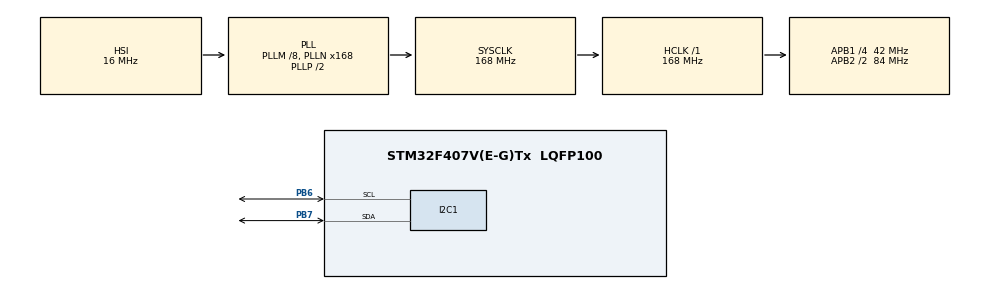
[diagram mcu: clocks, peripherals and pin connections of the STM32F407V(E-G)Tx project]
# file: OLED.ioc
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ADC1.Channel-0\#ChannelRegularConversion=ADC_CHANNEL_TEMPSENSOR
ADC1.NbrOfConversionFlag=1
ADC1.master=1
Dma.I2C1_TX.0.Direction=DMA_MEMORY_TO_PERIPH
Dma.I2C1_TX.0.FIFOMode=DMA_FIFOMODE_DISABLE
Dma.I2C1_TX.0.Instance=DMA1_Stream6
Dma.I2C1_TX.0.MemDataAlignment=DMA_MDATAALIGN_BYTE
Dma.I2C1_TX.0.MemInc=DMA_MINC_ENABLE
Dma.I2C1_TX.0.Mode=DMA_NORMAL
Dma.I2C1_TX.0.PeriphDataAlignment=DMA_PDATAALIGN_BYTE
Dma.I2C1_TX.0.PeriphInc=DMA_PINC_DISABLE
Dma.I2C1_TX.0.Priority=DMA_PRIORITY_LOW
Dma.Request0=I2C1_TX
I2C1.I2C_Mode=I2C_Fast
Mcu.Family=STM32F4
Mcu.Name=STM32F407V(E-G)Tx
Mcu.Package=LQFP100
NVIC.DMA1_Stream6_IRQn=true\:0\:0\:false\:false\:true\:false\:true\:true
NVIC.I2C1_ER_IRQn=true\:0\:0\:false\:false\:true\:true\:true\:true
NVIC.I2C1_EV_IRQn=true\:0\:0\:false\:false\:true\:true\:true\:true
NVIC.PriorityGroup=NVIC_PRIORITYGROUP_4
PA13.Mode=Serial_Wire
PA13.Signal=SYS_JTMS-SWDIO
PA14.Mode=Serial_Wire
PA14.Signal=SYS_JTCK-SWCLK
PB6.Mode=I2C
PB6.Signal=I2C1_SCL
PB7.Mode=I2C
PB7.Signal=I2C1_SDA
PH0-OSC_IN.Mode=HSE-External-Oscillator
PH0-OSC_IN.Signal=RCC_OSC_IN
PH1-OSC_OUT.Mode=HSE-External-Oscillator
PH1-OSC_OUT.Signal=RCC_OSC_OUT
ProjectManager.HeapSize=0x200
ProjectManager.StackSize=0x400
ProjectManager.TargetToolchain=STM32CubeIDE
RCC.48MHZClocksFreq_Value=84000000
RCC.AHBFreq_Value=168000000
RCC.APB1CLKDivider=RCC_HCLK_DIV4
RCC.APB1Freq_Value=42000000
RCC.APB1TimFreq_Value=84000000
RCC.APB2CLKDivider=RCC_HCLK_DIV2
RCC.APB2Freq_Value=84000000
RCC.APB2TimFreq_Value=168000000
RCC.CortexFreq_Value=168000000
RCC.HCLKFreq_Value=168000000
RCC.HSE_VALUE=25000000
RCC.HSI_VALUE=16000000
RCC.PLLM=8
RCC.PLLN=168
RCC.SYSCLKFreq_VALUE=168000000
RCC.SYSCLKSource=RCC_SYSCLKSOURCE_PLLCLK
RCC.VCOOutputFreq_Value=336000000
RTC.Date=28
RTC.Hours=20
RTC.Minutes=47
RTC.Month=RTC_MONTH_DECEMBER
RTC.WeekDay=RTC_WEEKDAY_THURSDAY
RTC.Year=24
VP_ADC1_TempSens_Input.Mode=IN-TempSens
VP_RTC_VS_RTC_Activate.Mode=RTC_Enabled
VP_RTC_VS_RTC_Calendar.Mode=RTC_Calendar
board=custom

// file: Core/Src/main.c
/* USER CODE BEGIN Header */
/**
  ******************************************************************************
  * @file           : main.c
  * @brief          : Main program body
  ******************************************************************************
  * @attention
  *
  * Copyright (c) 2023 STMicroelectronics.
  * All rights reserved.
  *
  * This software is licensed under terms that can be found in the LICENSE file
  * in the root directory of this software component.
  * If no LICENSE file comes with this software, it is provided AS-IS.
  *
  ******************************************************************************
  */
/* USER CODE END Header */
#include "main.h"
#include "adc.h"
#include "dma.h"
#include "i2c.h"
#include "rtc.h"
#include "gpio.h"

/* USER CODE BEGIN Includes */
#include <ic1306.h>
/* USER CODE END Includes */

/* USER CODE BEGIN PV */

RTC_TimeTypeDef sTime = {0};
RTC_DateTypeDef DateToUpdate = {0};

/* USER CODE END PV */

void SystemClock_Config(void);

int main(void)
{

  /* MCU Configuration--------------------------------------------------------*/

  /* Reset of all peripherals, Initializes the Flash interface and the Systick. */
  HAL_Init();

  /* Configure the system clock */
  SystemClock_Config();

  /* Initialize all configured peripherals */
  MX_GPIO_Init();
  MX_DMA_Init();
  MX_I2C1_Init();
  MX_RTC_Init();
  MX_ADC1_Init();
  /* USER CODE BEGIN 2 */
  display_init (0x30,0x22);

  display_clear(0,7);

 // display_MediumPrint(3,1,"Hello,");
 // display_MediumPrint(3,4,"PRO!");

  /* USER CODE END 2 */

  /* Infinite loop */
  /* USER CODE BEGIN WHILE */

 char trans_str[64] = {0,};
 int32_t ts = 0;
 while (1)
  {
  HAL_RTC_GetTime(&hrtc, &sTime, RTC_FORMAT_BIN); // RTC_FORMAT_BIN , RTC_FORMAT_BCD
  snprintf(trans_str, 63, " %02d:%02d:%02d\n", sTime.Hours, sTime.Minutes, sTime.Seconds);
  display_MediumPrint(0,1,trans_str);

  HAL_RTC_GetDate(&hrtc, &DateToUpdate, RTC_FORMAT_BIN);
  HAL_ADC_Start(&hadc1);
  HAL_ADC_PollForConversion(&hadc1, 100);
  ts = HAL_ADC_GetValue(&hadc1);
  snprintf(trans_str, 63, "Ts %d\n", ts);
  display_MediumPrint(2,3,trans_str);
  //temp = (Vtemp -tV_25)/tSlope + 25; (Vtemp-0,76V)/2,5mV
  snprintf(trans_str, 63, "Temp %d\n",(ts*33-31130)/102+25);
  display_MediumPrint(2,6,trans_str);

  HAL_RTC_GetDate(&hrtc, &DateToUpdate, RTC_FORMAT_BIN);
  snprintf(trans_str, 63, "%d-%02d-20%d\n", DateToUpdate.Date, DateToUpdate.Month, DateToUpdate.Year);
  //display_MediumPrint(0,4,trans_str);
  HAL_Delay(1000);
    /* USER CODE END WHILE */

  }
}

void SystemClock_Config(void)
{
  RCC_OscInitTypeDef RCC_OscInitStruct = {0};
  RCC_ClkInitTypeDef RCC_ClkInitStruct = {0};

  /** Configure the main internal regulator output voltage
  */
  __HAL_RCC_PWR_CLK_ENABLE();
  __HAL_PWR_VOLTAGESCALING_CONFIG(PWR_REGULATOR_VOLTAGE_SCALE1);

  /** Initializes the RCC Oscillators according to the specified parameters
  * in the RCC_OscInitTypeDef structure.
  */
  RCC_OscInitStruct.OscillatorType = RCC_OSCILLATORTYPE_HSI|RCC_OSCILLATORTYPE_LSI;
  RCC_OscInitStruct.HSIState = RCC_HSI_ON;
  RCC_OscInitStruct.HSICalibrationValue = RCC_HSICALIBRATION_DEFAULT;
  RCC_OscInitStruct.LSIState = RCC_LSI_ON;
  RCC_OscInitStruct.PLL.PLLState = RCC_PLL_ON;
  RCC_OscInitStruct.PLL.PLLSource = RCC_PLLSOURCE_HSI;
  RCC_OscInitStruct.PLL.PLLM = 8;
  RCC_OscInitStruct.PLL.PLLN = 168;
  RCC_OscInitStruct.PLL.PLLP = RCC_PLLP_DIV2;
  RCC_OscInitStruct.PLL.PLLQ = 4;
  if (HAL_RCC_OscConfig(&RCC_OscInitStruct) != HAL_OK)
  {
    Error_Handler();
  }

  /** Initializes the CPU, AHB and APB buses clocks
  */
  RCC_ClkInitStruct.ClockType = RCC_CLOCKTYPE_HCLK|RCC_CLOCKTYPE_SYSCLK
                              |RCC_CLOCKTYPE_PCLK1|RCC_CLOCKTYPE_PCLK2;
  RCC_ClkInitStruct.SYSCLKSource = RCC_SYSCLKSOURCE_PLLCLK;
  RCC_ClkInitStruct.AHBCLKDivider = RCC_SYSCLK_DIV1;
  RCC_ClkInitStruct.APB1CLKDivider = RCC_HCLK_DIV4;
  RCC_ClkInitStruct.APB2CLKDivider = RCC_HCLK_DIV2;

  if (HAL_RCC_ClockConfig(&RCC_ClkInitStruct, FLASH_LATENCY_5) != HAL_OK)
  {
    Error_Handler();
  }
}

void Error_Handler(void)
{
  __disable_irq();
  while (1)
  {
  }
}
